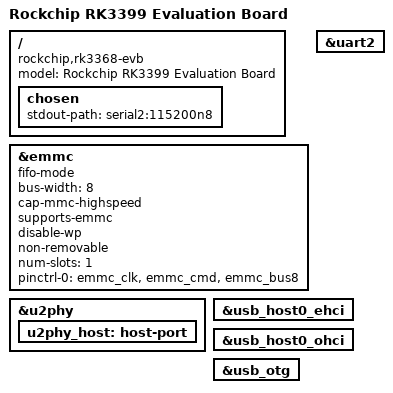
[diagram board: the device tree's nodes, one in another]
/*
 * SPDX-License-Identifier:     GPL-2.0+
 *
 * (C) Copyright 2018 Rockchip Electronics Co., Ltd
 */

/dts-v1/;
#include "rk3368.dtsi"
#include "rk3368-u-boot.dtsi"
#include <dt-bindings/input/input.h>

/ {
	model = "Rockchip RK3399 Evaluation Board";
	compatible = "rockchip,rk3368-evb", "rockchip,rk3368";

	chosen {
		stdout-path = "serial2:115200n8";
	};
};

&emmc {
	fifo-mode;
	bus-width = <8>;
	cap-mmc-highspeed;
	supports-emmc;
	disable-wp;
	non-removable;
	num-slots = <1>;
	pinctrl-names = "default";
	pinctrl-0 = <&emmc_clk &emmc_cmd &emmc_bus8>;
	status = "okay";
};

&uart2 {
	status = "okay";
};

&u2phy {
	status = "okay";

	u2phy_host: host-port {
		status = "okay";
	};
};

&usb_host0_ehci {
	status = "okay";
};

&usb_host0_ohci {
	status = "okay";
};

&usb_otg {
	status = "okay";
};
